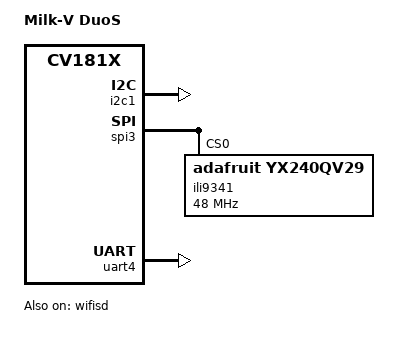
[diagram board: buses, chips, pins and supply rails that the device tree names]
/dts-v1/;
#include "cv181x_base_riscv.dtsi"
#include "cv181x_asic_bga.dtsi"
#include "cv181x_asic_emmc.dtsi"
#include "cv181x_default_memmap.dtsi"

&mipi_rx{
	snsr-reset = <&porta 2 GPIO_ACTIVE_LOW>, <&porta 2 GPIO_ACTIVE_LOW>, <&porta 2 GPIO_ACTIVE_LOW>;
};

&dac{
	/delete-property/ mute-gpio-l;
	/delete-property/ mute-gpio-r;
};

&i2c0 {
	status = "disabled";
};

&i2c1 {
	status = "okay";
};

&spi3 {
	status = "okay";
	/delete-node/ spidev@0;

	st7789v: st7789v@0{
		compatible = "sitronix,st7789v";
		reg = <0>;
		status = "disabled";
		spi-max-frequency = <48000000>;
		spi-cpol;
		spi-cpha;
		rotate = <0>;
		fps = <60>;
		rgb;
		buswidth = <8>;

		dc = <&porta 18 GPIO_ACTIVE_HIGH>;
		reset = <&porta 28 GPIO_ACTIVE_HIGH>;

		debug = <0x0>;
	};

	ili9341: ili9341@0 {
		compatible = "adafruit,yx240qv29", "ilitek,ili9341";
		reg = <0>;
		status = "okay";
		spi-max-frequency = <48000000>;
		spi-cpol;
		spi-cpha;
		rotate = <0>;
		fps = <60>;
		rgb;
		buswidth = <8>;

		dc = <&porta 18 GPIO_ACTIVE_HIGH>;
		reset = <&porta 28 GPIO_ACTIVE_HIGH>;

		debug = <0x0>;
	};
};

&usb {
	vbus-gpio = <&portb 6 0>;
};

&wifisd {
	status = "okay";
	cap-sd-highspeed;
	sd-uhs-sdr25;
	sd-uhs-ddr50;
	sd-uhs-sdr104;
	min-frequency = <400000>;
	max-frequency = <187500000>;
};

&wifi_pin {
	compatible = "cvitek,wifi-pin";
	poweron-gpio = <&porta 15 GPIO_ACTIVE_HIGH>;
	wakeup-gpio = <&porte 7 GPIO_ACTIVE_HIGH>;
};

&uart4 {
	status = "okay";
};

/ {
	model = "Milk-V DuoS";
};

